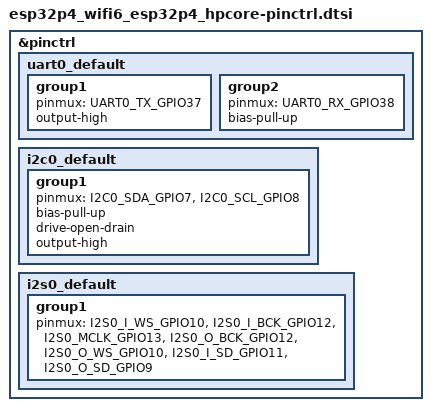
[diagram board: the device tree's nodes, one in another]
/*
 * Copyright (c) 2026 Hongquan Li
 *
 * SPDX-License-Identifier: Apache-2.0
 */

#include <zephyr/dt-bindings/pinctrl/esp-pinctrl-common.h>
#include <zephyr/dt-bindings/pinctrl/esp32p4-pinctrl.h>
#include <zephyr/dt-bindings/pinctrl/esp32p4-gpio-sigmap.h>

&pinctrl {
	uart0_default: uart0_default {
		group1 {
			pinmux = <UART0_TX_GPIO37>;
			output-high;
		};

		group2 {
			pinmux = <UART0_RX_GPIO38>;
			bias-pull-up;
		};
	};

	i2c0_default: i2c0_default {
		group1 {
			pinmux = <I2C0_SDA_GPIO7>,
				 <I2C0_SCL_GPIO8>;
			bias-pull-up;
			drive-open-drain;
			output-high;
		};
	};

	i2s0_default: i2s0_default {
		group1 {
			/* The I2S_RX unit runs in slave mode in full-duplex
			 * configurations and takes BCK/WS from its input
			 * signals, so route them from the same pins the TX
			 * unit drives (like the ESP-IDF full-duplex setup
			 * does). List them before the TX outputs: each pin
			 * has a single output-select register and the last
			 * matrix_out wins, while input routing is kept in
			 * separate registers.
			 */
			pinmux = <I2S0_I_WS_GPIO10>,
				 <I2S0_I_BCK_GPIO12>,
				 <I2S0_MCLK_GPIO13>,
				 <I2S0_O_BCK_GPIO12>,
				 <I2S0_O_WS_GPIO10>,
				 <I2S0_I_SD_GPIO11>,
				 <I2S0_O_SD_GPIO9>;
		};
	};
};
